# apollo3 register map
Vendor: Ambiq Micro; Series: Apollo; File version: 1.0
CPU: CM4 r1p0, little endian, MPU, FPU, 3 interrupt priority bits
Registers are 32-bit, read-write, reset 0x0 unless marked. A register's access mark holds for its fields unless they carry their own. Offsets are from the block's base; [hi:lo] are bit positions; 'fields as' and 'values as' point back to an identical list.

## BLEIF — BLE Interface
Base 0x5000C000
0x00 FIFO — Provides direct random access to both input and output fifos. The state of the FIFO is not distured by reading these locations (ie no POP will be done). FIFO0 is accessible from addresses 0x0 - 0x1C, and is used for data outuput from the IOM to external devices. These FIFO locations can be read and written directly. FIFO locations 0x20 - 0x3C provide read only access to the input fifo. These FIFO locations cannot be directly written by the MCU, and are updated only by the internal hardware. Writes to the FIFO0 will take effect immediately. The currently FIFO pointers in register FIFOLOC indicate the current offset into each FIFO0 for the read and write operations. Access to the FIFOs can only be done in word increments; Byte access and writes are not supported. For push and pop style access to FIFO0 can be done using the FIFOPOP and FIFOPUSH registers below.
  [31:0] FIFO — FIFO direct access. Only locations 0 - 3F will return valid information.
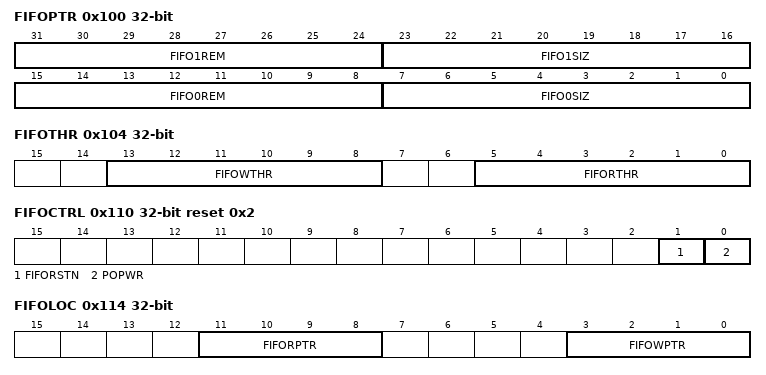
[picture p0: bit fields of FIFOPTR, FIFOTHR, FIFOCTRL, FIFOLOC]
0x100 FIFOPTR — Provides the current valid byte count of data within the FIFO as seen from the internal state machines. FIFO0 is dedicated to outgoing transactions and FIFO1 is dedicated to incoming transactions. All counts are specified in units of bytes.
  [31:24] FIFO1REM — The number of remaining data bytes slots currently in FIFO 1 (written by interface, read by MCU)
  [23:16] FIFO1SIZ — The number of valid data bytes currently in FIFO 1 (written by interface, read by MCU)
  [15:8] FIFO0REM — The number of remaining data bytes slots currently in FIFO 0 (written by MCU, read by interface)
  [7:0] FIFO0SIZ — The number of valid data bytes currently in the FIFO 0 (written by MCU, read by interface)
0x104 FIFOTHR — Sets the threshold values for incoming and outgoing transactions. The threshold values are used to assert the interrupt if enabled, and also used during DMA to set the transfer size as a result of DMATHR trigger. The WTHR is used to indicate when there are more than WTHR bytes of open fifo locations available in the outgoing FIFO (FIFO0). The intended use to invoke an interrupt or DMA transfer that will refill the FIFO with a byte count up to this value. The RTHR is used to indicate when there are more than RTHR bytes in the incoming FIFO (FIFO1) and a data transfer of this size can be supported, either through direct POP of the FIFO, or through DMA. The value of both RTHR and WTHR are also used to set the data transfer size of DMA operations if DMATHR trigger is enabled.
  [13:8] FIFOWTHR — FIFO write threshold in bytes. A value of 0 will disable the write FIFO level from activating the threshold interrupt. If this field is non-zero, it will trigger a threshold interrupt when the write fifo contains FIFOWTHR free bytes, as indicated by the FIFO0REM field. This is intended to signal when a transfer of FIFOWTHR bytes can be done from the host to the IOM write fifo to support large IOM write operations.
  [5:0] FIFORTHR — FIFO read threshold in bytes. A value of 0 will disable the read FIFO level from activating the threshold interrupt. If this field is non-zero, it will trigger a threshold interrupt when the read fifo contains FIFORTHR valid bytes of data, as indicated by the FIFO1SIZ field. This is intended to signal when a data transfer of FIFORTHR bytes can be done from the IOM module to the host via the read fifo to support large IOM read operations.
0x108 FIFOPOP — Will advance the internal read pointer of the incoming FIFO (FIFO1) when read, if POPWR is not active. If POPWR is active, a write to this register is needed to advance the internal FIFO pointer.
  [31:0] FIFODOUT — This register will return the read data indicated by the current read pointer on reads. If the POPWR control bit in the FIFOCTRL register is reset (0), the fifo read pointer will be advanced by one word as a result of the read. If the POPWR bit is set (1), the fifo read pointer will only be advanced after a write operation to this register. The write data is ignored for this register. If less than a even word multiple is available, and the command is completed, the module will return the word containing these bytes and undetermined data in the unused fields of the word.
0x10C FIFOPUSH — Will write new data into the outgoing FIFO and advance the internal write pointer.
  [31:0] FIFODIN — This register is used to write the FIFORAM in FIFO mode and will cause a push event to occur to the next open slot within the FIFORAM. Writing to this register will cause the write point to increment by 1 word(4 bytes).
0x110 FIFOCTRL reset 0x2 — Provides controls for the operation of the internal FIFOs. Contains fields used to control the operation of the POP register, and also controls to reset the internal pointers of the FIFOs.
  [1] FIFORSTN — Active low manual reset of the fifo. Write to 0 to reset fifo, and then write to 1 to remove the reset.
  [0] POPWR — Selects the mode in which 'pop' events are done for the fifo read operations. A value of '1' will prevent a pop event on a read operation, and will require a write to the FIFOPOP register to create a pop event. A value of '0' in this register will allow a pop event to occur on the read of the FIFOPOP register, and may cause inadvertant fifo pops when used in a debugging mode.
0x114 FIFOLOC — Provides a read only value of the current read and write pointers. This register is read only and can be used alogn with the FIFO direct access method to determine the next data to be used for input and output functions.
  [11:8] FIFORPTR — Current FIFO read pointer. Used to index into the incoming FIFO (FIFO1), which is used to store read data returned from external devices during a read operation.
  [3:0] FIFOWPTR — Current FIFO write pointer. Value is the index into the outgoing FIFO (FIFO0), which is used during write operations to external devices.
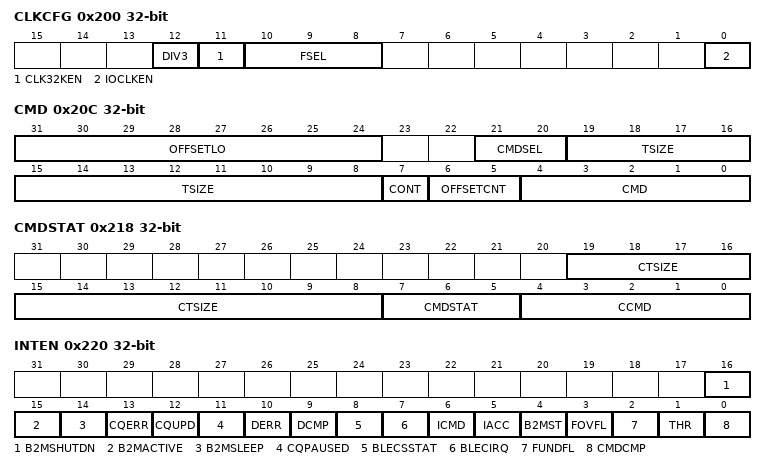
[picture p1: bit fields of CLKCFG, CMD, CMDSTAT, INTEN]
0x200 CLKCFG — Provides clock related controls used internal to the BLEIF module, and enablement of 32KHz clock to the BLE Core module. The internal clock sourced is selected via the FSEL and can be further divided by 3 using the DIV3 control. This register is also used to enable the clock, which must be done prior to performing any IO transactions.
  [12] DIV3 — Enable of the divide by 3 of the source IOCLK.
  [11] CLK32KEN — Enable for the 32Khz clock to the BLE module
  [10:8] FSEL — Select the input clock frequency.
    0=MIN_PWR (Selects the minimum power clock. This setting should be used whenever the IOM is not active.); 1=HFRC (Selects the HFRC as the input clock.); 2=HFRC_DIV2 (Selects the HFRC / 2 as the input clock.); 3=HFRC_DIV4 (Selects the HFRC / 4 as the input clock.); 4=HFRC_DIV8 (Selects the HFRC / 8 as the input clock.); 5=HFRC_DIV16 (Selects the HFRC / 16 as the input clock.); 6=HFRC_DIV32 (Selects the HFRC / 32 as the input clock.); 7=HFRC_DIV64 (Selects the HFRC / 64 as the input clock.)
  [0] IOCLKEN — Enable for the interface clock. Must be enabled prior to executing any IO operations.
0x20C CMD — Writes to this register will start an IO transaction, as well as set various parameters for the command itself. Reads will return the command value written to the CMD register. To read the number of bytes that have yet to be transferred, refer to the CTSIZE field within the CMDSTAT register.
  [31:24] OFFSETLO — This register holds the low order byte of offset to be used in the transaction. The number of offset bytes to use is set with bits 1:0 of the command. Offset bytes are transferred starting from the highest byte first.
  [21:20] CMDSEL — Command Specific selection information
  [19:8] TSIZE — Defines the transaction size in bytes. The offset transfer is not included in this size.
  [7] CONT — Contine to hold the bus after the current transaction if set to a 1 with a new command issued.
  [6:5] OFFSETCNT — Number of offset bytes to use for the command - 0, 1, 2, 3 are valid selections. The second (byte 1) and third byte (byte 2) are read from the OFFSETHI register, and the low order byte is pulled from this register in the OFFSETLO field. Offset bytes are transmitted highest byte first. EG if offsetcnt == 3, OFFSETHI[15:8] will be transmitted first, then OFFSETHI[7:0] then OFFSETLO. If offsetcnt == 2, OFFSETHI[7:0] will be transmitted, then OFFSETLO. If offsetcnt == 1, only OFFSETLO will be transmitted. Offset bytes are always transmitted MSB first, regardless of the value of the LSB control bit within the module configuration.
  [4:0] CMD — Command for submodule.
    1=WRITE (Write command using count of offset bytes specified in the OFFSETCNT field); 2=READ (Read command using count of offset bytes specified in the OFFSETCNT field)
0x210 CMDRPT — Will repeat the next command for CMDRPT number of times. If CMDRPT is set to 1, the next command will be done 2 times in series. A repeat count of up to 31 is possible. Each command will be done as a seperate command, but the data will be treated as packed, and aligned to byte boundaries. This differs when executing seperate commands without the CMDRPT set, as the data for each transaction is word aligned and any unused byte locations will be filled with 0 for read operations, or discarded for write operations. For repeated commands (CMDRPT is nonzero), the data is packed and no bytes will be filled or discarded until the final command is done. The register value is decremented for each repeated command and at the end of the repeated command set, will be set to zero. If subsequent commands are to be repeated, this register must be written again.
  [4:0] CMDRPT — Count of number of times to repeat the next command.
0x214 OFFSETHI — Provides the high order bytes of 2 or 3 byte offset transactions of the current command. Usage of these bytes is dependant on the offsetcnt field in the CMD register. If the offsetcnt == 3, the data located at OFFSETHI[15:0] will first be transmitted, followed by OFFSETHI[7:0], followed by OFFSETLO (in the CMD register) prior to sending or receiving any transaction data (if programed via TSIZE field in the CMD register). The offset bytes are always transmitted MSB first for all modules.
  [15:0] OFFSETHI — Holds the high order bytes of the 2 or 3 byte offset phase of a transaction.
0x218 CMDSTAT — Provides staus on the execution of the command currently in progress. The fields in this register will reflect the real time status of the internal state machines and data transfers within the IOM. These are read only fields and writes to the registers are ignored.
  [19:8] CTSIZE — The current number of bytes still to be transferred with this command. This field will count down to zero.
  [7:5] CMDSTAT — The current status of the command execution.
    1=ERR (Error encountered with command); 2=ACTIVE (Actively processing command); 4=IDLE (Idle state, no active command, no error); 6=WAIT (Command in progress, but waiting on data from host)
  [4:0] CCMD — current command that is being executed
0x220 INTEN — Set bits in this register to allow this module to generate the corresponding interrupt.
  [16] B2MSHUTDN — Revision A: The B2M_STATE from the BLE Core transitioned into shutdown state Revision B: Falling BLE Core Status signal. Asserted when the BLE_STATUS signal from the BLE Core is de-asserted (1 -> 0)
  [15] B2MACTIVE — Revision A: The B2M_STATE from the BLE Core transitioned into the active state Revision B: Falling BLE Core IRQ signal. Asserted when the BLE_IRQ signal from the BLE Core is de-asserted (1 -> 0)
  [14] B2MSLEEP — The B2M_STATE from the BLE Core transitioned into the sleep state
  [13] CQERR — Command queue error during processing. When an error occurs, the system will stop processing and halt operations to allow software to take recovery actions
  [12] CQUPD — Command queue write operation executed a register write with the register address bit 0 set to 1. The low address bits in the CQ address fields are unused and bit 0 can be used to trigger an interrupt to indicate when this register write is performed by the CQ operation.
  [11] CQPAUSED — Command queue is paused due to an active event enabled in the PAUSEEN register. The interrupt is posted when the event is enabled within the PAUSEEN register, the mask is active in the CQIRQMASK field and the event occurs.
  [10] DERR — DMA Error encountered during the processing of the DMA command. The DMA error could occur when the memory access specified in the DMA operation is not available or incorrectly specified.
  [9] DCMP — DMA Complete. Processing of the DMA operation has completed and the DMA submodule is returned into the idle state
  [8] BLECSSTAT — BLE Core SPI Status interrupt. Asserted when the SPI_STATUS signal from the BLE Core is asserted, indicating that SPI writes can be done to the BLE Core. Transfers to the BLE Core should only be done when this signal is high.
  [7] BLECIRQ — BLE Core IRQ signal. Asserted when the BLE_IRQ signal from the BLE Core is asserted, indicating the availability of read data from the BLE Core.
  [6] ICMD — illegal command interrupt. Asserted when a command is written when an active command is in progress.
  [5] IACC — illegal FIFO access interrupt. Asserted when there is a overflow or underflow event
  [4] B2MST — B2M State change interrupt. Asserted on any change in the B2M_STATE signal from the BLE Core.
  [3] FOVFL — Write FIFO Overflow interrupt. This occurs when software tries to write to a full fifo. The current operation does not stop.
  [2] FUNDFL — Read FIFO Underflow interrupt. Asserted when a pop operation is done to a empty read FIFO.
  [1] THR — FIFO Threshold interrupt. For write operations, asserted when the number of free bytes in the write FIFO equals or exceeds the WTHR field. For read operations, asserted when the number of valid bytes in the read FIFO equals of exceeds the value set in the RTHR field.
  [0] CMDCMP — Command Complete interrupt. Asserted when the current operation has completed. For repeated commands, this will only be asserted when the final repeated command is completed.
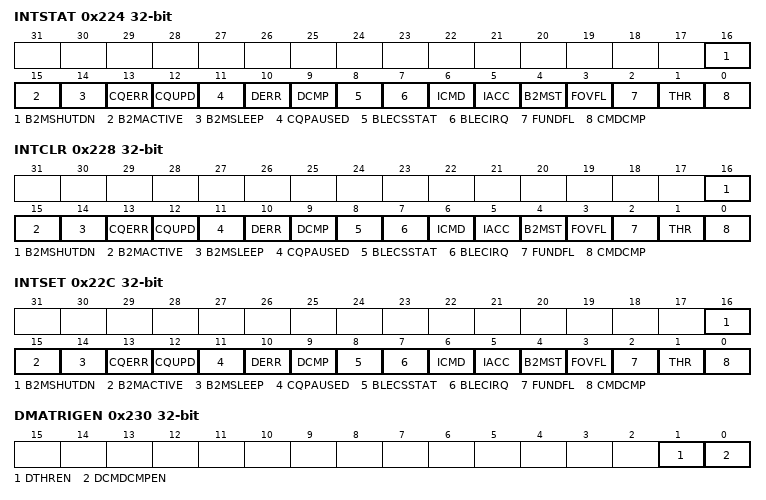
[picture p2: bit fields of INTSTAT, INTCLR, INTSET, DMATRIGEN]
0x224 INTSTAT — Read bits from this register to discover the cause of a recent interrupt.
  fields as INTEN
0x228 INTCLR — Write a 1 to a bit in this register to clear the interrupt status associated with that bit.
  fields as INTEN
0x22C INTSET — Write a 1 to a bit in this register to instantly generate an interrupt from this module. (Generally used for testing purposes).
  fields as INTEN
0x230 DMATRIGEN — Provides control on which event will trigger the DMA transfer after the DMA operation is setup and enabled. The trigger event will cause a number of bytes (depending on trigger event) to be transferred via the DMA operation, and can be used to adjust the latency of data to/from the IOM module to/from the dma target. DMA transfers are broken into smaller transfers internally of up to 16 bytes each, and multiple trigger events can be used to complete the entire programmed DMA transfer.
  [1] DTHREN — Trigger DMA upon THR level reached. For M2P DMA operations (IOM writes), the trigger will assert when the write FIFO has (WTHR/4) number of words free in the write FIFO, and will transfer (WTHR/4) number of words or, if the number of words left to transfer is less than the WTHR value, will transfer the remaining byte count. For P2M DMA operations, the trigger will assert when the read FIFO has (RTHR/4) words available in the read FIFO, and will transfer (RTHR/4) words to SRAM. This trigger will NOT assert when the transaction completes and there are less than RTHR bytes left in the fifo, since the RTHR has not been reached. In this case, enabling the CMDCMP trigger will transfer the remaining data from the commmand. If the CMDCMP trigger is not enabled, the module will initiate a transfer when the amount of data in the FIFO is equal to or greater than the remaining data in the DMA. In cases where one DMA setup covers multiple commands, this will only occur at the end of the last transaction when the DMA is near complete.
  [0] DCMDCMPEN — Trigger DMA upon command complete. Enables the trigger of the DMA when a command is completed. When this event is triggered, the number of words transferred will be the lesser of the remaining TOTCOUNT bytes, or the number of bytes in the FIFO when the command completed. If this is disabled, and the number of bytes in the FIFO is equal or greater than the TOTCOUNT bytes, a transfer of TOTCOUNT bytes will be done to ensure read data is stored when the DMA is completed.
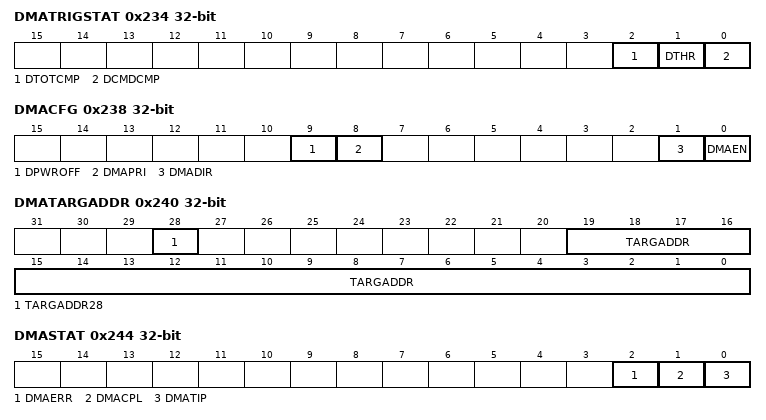
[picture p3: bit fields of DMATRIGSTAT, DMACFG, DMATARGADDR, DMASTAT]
0x234 DMATRIGSTAT — Provides the status of trigger events that have occurred for the transaction. Some of the bits are read only and some can be reset via a write of 0.
  [2] DTOTCMP — DMA triggered when DCMDCMP = 0, and the amount of data in the FIFO was enough to complete the DMA operation (greater than or equal to current TOTCOUNT) when the command completed. This trigger is default active when the DCMDCMP trigger is disabled and there is enough data in the FIFO to complete the DMA operation.
  [1] DTHR — Triggered DMA from THR event. Bit is read only and can be cleared by disabling the DTHR trigger enable or by disabling DMA.
  [0] DCMDCMP — Triggered DMA from Command complete event. Bit is read only and can be cleared by disabling the DCMDCMP trigger enable or by disabling DMA.
0x238 DMACFG — Configuration control of the DMA process, including the direction of DMA, and enablement of DMA
  [9] DPWROFF — Power off module after DMA is complete. If this bit is active, the module will request to power off the supply it is attached to. If there are other units still requiring power from the same domain, power down will not be performed.
    0=DIS (Power off disabled); 1=EN (Power off enabled)
  [8] DMAPRI — Sets the Priority of the DMA request
    0=LOW (Low Priority (service as best effort)); 1=HIGH (High Priority (service immediately))
  [1] DMADIR — Direction
    0=P2M (Peripheral to Memory (SRAM) transaction. To be set when doing IOM read operations, ie reading data from external devices.); 1=M2P (Memory to Peripheral transaction. To be set when doing IOM write operations, ie writing data to external devices.)
  [0] DMAEN — DMA Enable. Setting this bit to EN will start the DMA operation. This should be the last DMA related register set prior to issuing the command
    0=DIS (Disable DMA Function); 1=EN (Enable DMA Function)
0x23C DMATOTCOUNT — Contains the number of bytes to be transferred for this DMA transaction. This register is decremented as the data is transferred, and will be 0 at the completion of the DMA operation.
  [11:0] TOTCOUNT — Triggered DMA from Command complete event occured. Bit is read only and can be cleared by disabling the DTHR trigger enable or by disabling DMA.
0x240 DMATARGADDR — The source or destination address internal the SRAM for the DMA data. For write operations, this can only be SRAM data (ADDR bit 28 = 1); For read operations, this can ve either SRAM or FLASH (ADDR bit 28 = 0)
  [28] TARGADDR28 — Bit 28 of the target byte address for source of DMA (either read or write). In cases of non-word aligned addresses, the DMA logic will take care for ensuring only the target bytes are read/written. Setting to '1' will select the SRAM. Setting to '0' will select the flash
  [19:0] TARGADDR — Bits [19:0] of the target byte address for source of DMA (either read or write). The address can be any byte alignment, and does not have to be word aligned. In cases of non-word aligned addresses, the DMA logic will take care for ensuring only the target bytes are read/written.
0x244 DMASTAT — Status of the DMA operation currently in progress.
  [2] DMAERR — DMA Error. This active high bit signals that an error was encountered during the DMA operation.
  [1] DMACPL — DMA Transfer Complete. This signals the end of the DMA operation. This bit can be cleared by writing to 0.
  [0] DMATIP — DMA Transfer In Progress indicator. 1 will indicate that a DMA transfer is active. The DMA transfer may be waiting on data, transferring data, or waiting for priority. All of these will be indicated with a 1. A 0 will indicate that the DMA is fully complete and no further transactions will be done. This bit is read only.
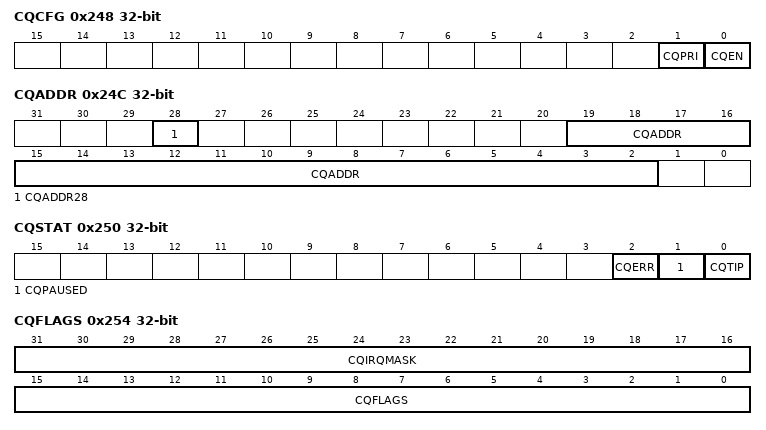
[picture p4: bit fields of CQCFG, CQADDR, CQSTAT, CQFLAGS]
0x248 CQCFG — Controls parameters and options for execution of the command queue operation. To enable command queue, create this in memory, set the address, and enable it with a write to CQEN
  [1] CQPRI — Sets the Priority of the command queue dma request.
    values as DMACFG.DMAPRI
  [0] CQEN — Command queue enable. When set, will enable the processing of the command queue and fetches of address/data pairs will proceed from the word address within the CQADDR register. Can be disabled using a CQ executed write to this bit as well.
    0=DIS (Disable CQ Function); 1=EN (Enable CQ Function)
0x24C CQADDR — The SRAM address which will be fetched next execution of the CQ operation. This register is updated as the CQ operation progresses, and is the live version of the register. The register can also be written by the Command Queue operation itself, allowing the relocation of successive CQ fetches. In this case, the new CQ address will be used for the next CQ address/data fetch
  [28] CQADDR28 — Bit 28 of target byte address for source of CQ (read only). Used to denote Flash (0) or SRAM (1) access
  [19:2] CQADDR — Bits 19:2 of target byte address for source of CQ (read only). The buffer must be aligned on a word boundary
0x250 CQSTAT — Provides the status of the command queue operation. If the command queue is disabled, these bits will be cleared. The bits are read only
  [2] CQERR — Command queue processing Error. This active high bit signals that an error was encountered during the CQ operation.
  [1] CQPAUSED — Command queue operation is currently paused.
  [0] CQTIP — Command queue Transfer In Progress indicator. 1 will indicate that a CQ transfer is active and this will remain active even when paused waiting for external event.
0x254 CQFLAGS — Provides the current status of the SWFLAGS (bits 7:0) and the hardware generated flags (15:8). A '1' will pause the CQ operation if it the same bit is enabled in the CQPAUSEEN register
  [31:16] CQIRQMASK — Provides for a per-bit mask of the flags used to invoke an interrupt. A '1' in the bit position will enable the pause event to trigger the interrupt, if the CQWT_int interrupt is enabled. Bits definitions are the same as CQPAUSE
  [15:0] CQFLAGS — Current flag status (read-only). Bits [7:0] are software controllable and bits [15:8] are hardware status.
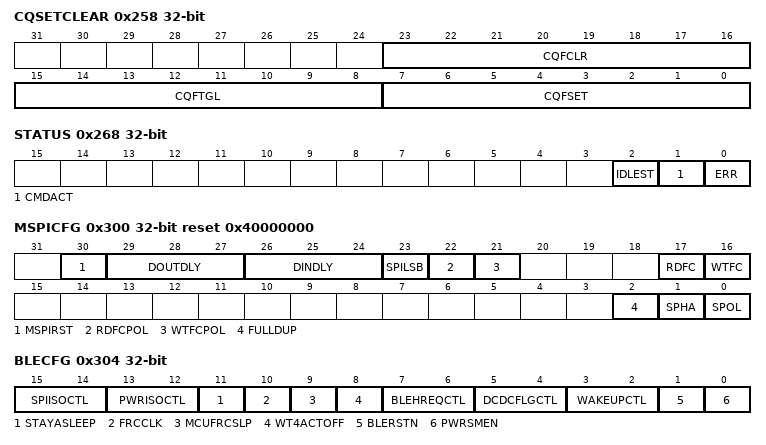
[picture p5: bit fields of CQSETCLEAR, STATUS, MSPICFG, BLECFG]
0x258 CQSETCLEAR — Set/Clear the command queue software pause flags on a per-bit basis. Contains 3 fields, allowing for setting, clearing or toggling the value in the software flags. Priority when the same bit is enabled in each field is toggle, then set, then clear.
  [23:16] CQFCLR — Clear CQFlag status bits. Will clear to 0 any SWFLAG with a '1' in the corresponding bit position of this field
  [15:8] CQFTGL — Toggle the indicated bit. Will toggle the value of any SWFLAG with a '1' in the corresponding bit position of this field
  [7:0] CQFSET — Set CQFlag status bits. Will set to 1 the value of any SWFLAG with a '1' in the corresponding bit position of this field
0x25C CQPAUSEEN — Enables a flag to pause an active command queue operation. If a bit is '1' and the corresponding bit in the CQFLAG register is '1', CQ processing will halt until either value is changed to '0'.
  [15:0] CQPEN — Enables the specified event to pause command processing when active
    0x8000=CNTEQ (Pauses command queue processing when HWCNT matches SWCNT); 0x4000=BLEXOREN (Pause command queue when input BLE bit XORed with SWFLAG4 is '1'); 0x2000=IOMXOREN (Pause command queue when input IOM bit XORed with SWFLAG3 is '1'); 0x1000=GPIOXOREN (Pause command queue when input GPIO irq_bit XORed with SWFLAG2 is '1'); 0x800=MSPI1XNOREN (Pause command queue when input MSPI1 bit XNORed with SWFLAG1 is '1'); 0x400=MSPI0XNOREN (Pause command queue when input MSPI0 bit XNORed with SWFLAG0 is '1'); 0x200=MSPI1XOREN (Pause command queue when input MSPI1 bit XORed with SWFLAG1 is '1'); 0x100=MSPI0XOREN (Pause command queue when input MSPI0 bit XORed with SWFLAG0 is '1'); 128=SWFLAGEN7 (Pause the command queue when software flag bit 7 is '1'.); 64=SWFLAGEN6 (Pause the command queue when software flag bit 7 is '1'); 32=SWFLAGEN5 (Pause the command queue when software flag bit 7 is '1'); 16=SWFLAGEN4 (Pause the command queue when software flag bit 7 is '1'); 8=SWFLAGEN3 (Pause the command queue when software flag bit 7 is '1'); 4=SWFLAGEN2 (Pause the command queue when software flag bit 7 is '1'); 2=SWFLAGEN1 (Pause the command queue when software flag bit 7 is '1'); 1=SWFLGEN0 (Pause the command queue when software flag bit 7 is '1')
0x260 CQCURIDX — Current index value, targeted to be written by register write operations within the command queue. This is compared to the CQENDIDX and will stop the CQ operation if bit 15 of the CQPAUSEEN is '1' and this current index equals the CQENDIDX register value. This will only pause when the values are equal.
  [7:0] CQCURIDX — Holds 8 bits of data that will be compared with the CQENDIX register field. If the values match, the IDXEQ pause event will be activated, which will cause the pausing of command quue operation if the IDXEQ bit is enabled in CQPAUSEEN.
0x264 CQENDIDX — End index value, targeted to be written by software to indicate the last valid register pair contained within the command queue. rgister write operations within the command queue. This is compared to the CQCURIDX and will stop the CQ operation if bit 15 of the CQPAUSEEN is '1' and this current index equals the CQCURIDX register value. This will only pause when the values are equal.
  [7:0] CQENDIDX — Holds 8 bits of data that will be compared with the CQCURIX register field. If the values match, the IDXEQ pause event will be activated, which will cause the pausing of command quue operation if the IDXEQ bit is enabled in CQPAUSEEN.
0x268 STATUS — General status of the IOM module command execution.
  [2] IDLEST — indicates if the active I/O state machine is IDLE. Note - The state machine could be in idle state due to holdoffs from data availability, or as the command gets propagated into the logic from the registers.
    1=IDLE (The I/O state machine is in the idle state.)
  [1] CMDACT — Indicates if the active I/O Command is currently processing a transaction, or command is complete, but the FIFO pointers are still syncronizing internally. This bit will go high at the start of the transaction, and will go low when the command is complete, and the data and pointers within the FIFO have been syncronized.
    1=ACTIVE (An I/O command is active. Indicates the active module has an active command and is processing this. De-asserted when the command is completed.)
  [0] ERR — Bit has been deprecated. Please refer to the other error indicators. This will always return 0.
    1=ERROR (Bit has been deprecated and will always return 0.)
0x300 MSPICFG reset 0x40000000 — Controls the configuration of the SPI master module, including POL/PHA, LSB, flow control, and delays for MISO and MOSI
  [30] MSPIRST — Bit is deprecated. setting it will have no effect.
  [29:27] DOUTDLY — Delay tap to use for the output signal (MOSI). This give more hold time on the output data.
  [26:24] DINDLY — Delay tap to use for the input signal (MISO). This gives more hold time on the input data.
  [23] SPILSB — Selects data transfer as MSB first (0) or LSB first (1) for the data portion of the SPI transaction. The offset bytes are always transmitted MSB first.
    0=MSB (Send and receive MSB bit first); 1=LSB (Send and receive LSB bit first)
  [22] RDFCPOL — Selects the read flow control signal polarity. When set, the clock will be held low until the flow control is de-asserted.
    0=NORMAL (SPI_STATUS signal from BLE Core high(1) creates flow control and new read spi transactions will not be started until the signal goes low.(default)); 1=INVERTED (SPI_STATUS signal from BLE Core low(0) creates flow control and new read spi transactions will not be started until the signal goes high.)
  [21] WTFCPOL — Selects the write flow control signal polarity. The transfers are halted when the selected flow control signal is OPPOSITE polarity of this bit. (For example: WTFCPOL = 0 will allow a SPI_STATUS=1 to pause transfers).
    0=NORMAL (SPI_STATUS signal from BLE Core high(1) creates flow control and new write spi transactions will not be started until the signal goes low.(default)); 1=INVERTED (SPI_STATUS signal from BLE Core high(1) creates low(0) control and new write spi transactions will not be started until the signal goes high.)
  [17] RDFC — Enables flow control of new read transactions based on the SPI_STATUS signal from the BLE Core.
    0=DIS (Read mode flow control disabled.); 1=EN (Read mode flow control enabled.)
  [16] WTFC — Enables flow control of new write transactions based on the SPI_STATUS signal from the BLE Core.
    0=DIS (Write mode flow control disabled.); 1=EN (Write mode flow control enabled.)
  [2] FULLDUP — Full Duplex mode. Capture read data during writes operations
  [1] SPHA — Selects the SPI phase; When 1, will shift the sampling edge by 1/2 clock.
    0=SAMPLE_LEADING_EDGE (Sample on the leading (first) clock edge, rising or falling dependant on the value of SPOL); 1=SAMPLE_TRAILING_EDGE (Sample on the trailing (second) clock edge, rising of falling dependant on the value of SPOL)
  [0] SPOL — This bit selects SPI polarity.
    0=CLK_BASE_0 (The initial value of the clock is 0.); 1=CLK_BASE_1 (The initial value of the clock is 1.)
0x304 BLECFG — Provides control of isolation and IO signals between the interface module and the BLE Core.
  [15:14] SPIISOCTL — Configuration of BLEH isolation controls for SPI related signals.
    3=ON (SPI signals from BLE Core to/from MCU Core are isolated.); 2=OFF (SPI signals from BLE Core to/from MCU Core are not isolated.); 0=AUTO (SPI signals from BLE Core to/from MCU Core are automatically isolated by the logic)
  [13:12] PWRISOCTL — Configuration of BLEH isolation control for power related signals.
    3=ON (BLEH power signal isolation to on (isolated).); 2=OFF (BLEH power signal isolation to off (not isolated).); 0=AUTO (BLEH Power signal isolation is controlled automatically through the interface logic)
  [11] STAYASLEEP — Set to prevent the BLE power control module from waking up the BLE Core after going into power down. To be used for graceful shutdown, set by software prior to powering off and will allow assertion of reset from sleep state.
  [10] FRCCLK — Force the clock in the BLEIF to be always running
  [9] MCUFRCSLP — Force power state machine to go to the sleep state. Intended for debug only. Has no effect on the actual BLE Core state, only the state of the BLEIF interface state machine.
  [8] WT4ACTOFF — Debug control of BLEIF power state machine. Allows transition into the active state in the BLEIF state without waiting for dcdc req from BLE Core.
  [7:6] BLEHREQCTL — BLEH power on request override. The value of this field will be sent to the BLE Core when the PWRSM is off. Otherwise, the value is supplied from internal logic.
    3=ON (BLEH Power-on reg signal is set to on (1).); 2=OFF (BLEH Power-on signal is set to off (0).); 0=AUTO (BLEH Power-on signal is controlled by the PWRSM logic and automatically controlled)
  [5:4] DCDCFLGCTL — DCDCFLG signal override. The value of this field will be sent to the BLE Core when the PWRSM is off. Otherwise, the value is supplied from internal logic.
    3=ON (DCDC Flag signal is set to on (1).); 2=OFF (DCDC Flag signal is set to off (0).); 0=AUTO (DCDC Flag signal is controlled by the PWRSM logic and automatically controlled)
  [3:2] WAKEUPCTL — WAKE signal override. Controls the source of the WAKE signal to the BLE Core.
    3=ON (Wake signal is set to on (1).); 2=OFF (Wake signal is set to off (0).); 0=AUTO (Wake signal is controlled by the PWRSM logic and automatically controlled)
  [1] BLERSTN — Reset line to the BLE Core. This will reset the BLE core when asserted ('0') and must be written to '1' prior to performing any BTLE related operations to the core.
    1=ACTIVE (The reset signal is active (0)); 0=INACTIVE (The reset signal is inactive (1))
  [0] PWRSMEN — Enable the power state machine for automatic sequencing and control of power states of the BLE Core module.
    1=ON (Internal power state machine is enabled and will sequence the BLEH power domain as indicated in the design document. Overrides for the power signals are not enabled.); 0=OFF (Internal power state machine is disabled and will not sequence the BLEH power domain. The values of the overrides will be used to drive the output sequencing signals)
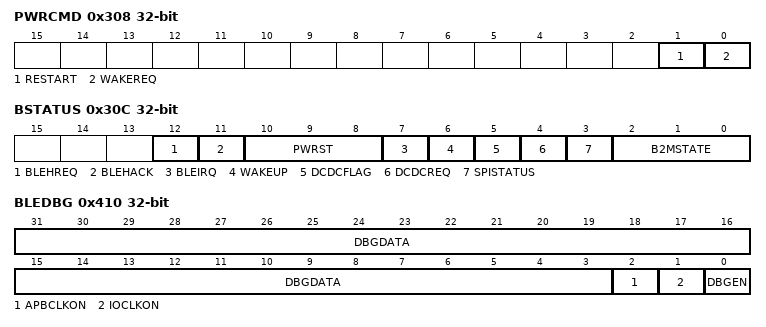
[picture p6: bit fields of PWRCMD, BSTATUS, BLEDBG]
0x308 PWRCMD — Sends power related commands to the power state machine in the BLE IF module.
  [1] RESTART — Restart the BLE Core after going into the shutdown state. Only valid when in the shutdown state.
  [0] WAKEREQ — Wake request from the MCU. When asserted (1), the BLE Interface logic will assert the wakeup request signal to the BLE Core. Only recognized when in the sleep state
0x30C BSTATUS — Status of the BLE Core interface signals
  [12] BLEHREQ — Value of the BLEHREQ signal to the power control unit. The BLEHREQ signal is sent from the BLEIF module to the power control module to request the BLEH power up. When the BLEHACK signal is asserted, BLEH power is stable and ready for use.
  [11] BLEHACK — Value of the BLEHACK signal from the power control unit. If the signal is '1', the BLEH power is active and ready for use.
  [10:8] PWRST — Current status of the power state machine
    0=OFF (Internal power state machine is disabled and will not sequence the BLEH power domain. The values of the overrides will be used to drive the output sequencing signals); 1=INIT (Initialization state. BLEH not powered); 2=PWRON (Waiting for the powerup of the BLEH); 3=ACTIVE (The BLE Core is powered and active); 6=SLEEP (The BLE Core has entered sleep mode and the power request is inactive); 4=SHUTDOWN (The BLE Core is in shutdown mode)
  [7] BLEIRQ — Status of the BLEIRQ signal from the BLE Core. A value of 1 idicates that read data is available in the core and a read operation needs to be performed.
  [6] WAKEUP — Value of the WAKEUP signal to the BLE Core . The WAKEUP signals is sent from the BLEIF to the BLECORE to request the BLE Core transition from sleep state to active state.
  [5] DCDCFLAG — Value of the DCDCFLAG signal to the BLE Core. The DCDCFLAG is a signal to the BLE Core indicating that the BLEH ppower is active.
  [4] DCDCREQ — Value of the DCDCREQ signal from the BLE Core. The DCDCREQ signal is sent from the core to the BLEIF module when the BLE core requires BLEH power to be active. When activated, this is indicated by DCDCFLAG going to 1.
  [3] SPISTATUS — Value of the SPISTATUS signal from the BLE Core. The signal is asserted when the BLE Core is able to accept write data via the SPI interface. Data should be transmitted to the BLE core only when this signal is 1. The hardware will automatically wait for this signal prior to performing a write operation if flow control is active.
  [2:0] B2MSTATE — State of the BLE Core logic.
    0=RESET (Reset State); 1=Sleep state; 2=Standby State; 3=Idle state; 4=Active state
0x410 BLEDBG — Debug control
  [31:3] DBGDATA — Debug data
  [2] APBCLKON — APBCLK debug clock control. Enable APB_CLK to be active when this bit is '1'. Otherwise, the clock is controlled with gating from the logic as needed.
  [1] IOCLKON — IOCLK debug clock control. Enable IO_CLK to be active when this bit is '1'. Otherwise, the clock is controlled with gating from the logic as needed.
  [0] DBGEN — Debug Enable. Setting this bit will enable the update of data within this register, otherwise it is clock gated for power savings

## Notices in the file
Copyright (C) 2012-2014 ARM Limited. All rights reserved.
Purpose: System Viewer Description (SVD) Example (Schema Version 1.1)
This is a description of a none-existent and incomplete device
for demonstration purposes only.
Redistribution and use in source and binary forms, with or without
modification, are permitted provided that the following conditions are met:
- Redistributions of source code must retain the above copyright
notice, this list of conditions and the following disclaimer.
- Redistributions in binary form must reproduce the above copyright
notice, this list of conditions and the following disclaimer in the
documentation and/or other materials provided with the distribution.
- Neither the name of ARM nor the names of its contributors may be used
to endorse or promote products derived from this software without
specific prior written permission.
THIS SOFTWARE IS PROVIDED BY THE COPYRIGHT HOLDERS AND CONTRIBUTORS "AS IS"
AND ANY EXPRESS OR IMPLIED WARRANTIES, INCLUDING, BUT NOT LIMITED TO, THE
IMPLIED WARRANTIES OF MERCHANTABILITY AND FITNESS FOR A PARTICULAR PURPOSE
ARE DISCLAIMED. IN NO EVENT SHALL COPYRIGHT HOLDERS AND CONTRIBUTORS BE
LIABLE FOR ANY DIRECT, INDIRECT, INCIDENTAL, SPECIAL, EXEMPLARY, OR
CONSEQUENTIAL DAMAGES (INCLUDING, BUT NOT LIMITED TO, PROCUREMENT OF
SUBSTITUTE GOODS OR SERVICES; LOSS OF USE, DATA, OR PROFITS; OR BUSINESS
INTERRUPTION) HOWEVER CAUSED AND ON ANY THEORY OF LIABILITY, WHETHER IN
CONTRACT, STRICT LIABILITY, OR TORT (INCLUDING NEGLIGENCE OR OTHERWISE)
ARISING IN ANY WAY OUT OF THE USE OF THIS SOFTWARE, EVEN IF ADVISED OF THE
POSSIBILITY OF SUCH DAMAGE.
